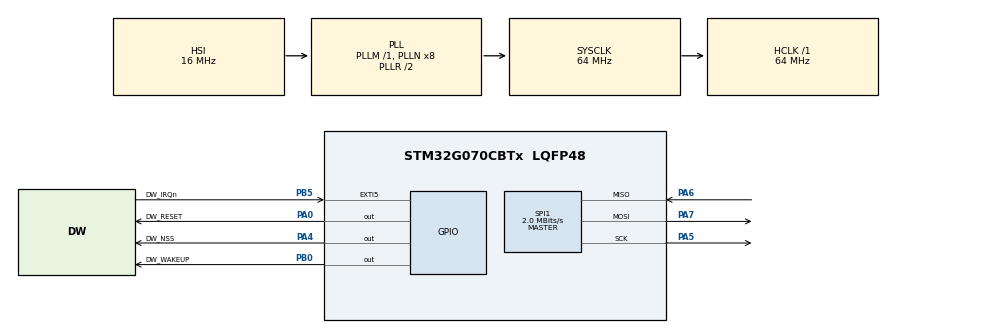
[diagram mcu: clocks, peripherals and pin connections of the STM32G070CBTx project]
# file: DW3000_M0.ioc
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Mcu.Family=STM32G0
Mcu.Name=STM32G070CBTx
Mcu.Package=LQFP48
NVIC.EXTI4_15_IRQn=true\:1\:0\:true\:false\:true\:true\:true\:true
PA0.GPIO_Label=DW_RESET
PA0.GPIO_Speed=GPIO_SPEED_FREQ_HIGH
PA0.Signal=GPIO_Output
PA13.Mode=Serial_Wire
PA13.Signal=SYS_SWDIO
PA14-BOOT0.Mode=Serial_Wire
PA14-BOOT0.Signal=SYS_SWCLK
PA4.GPIO_Label=DW_NSS
PA4.GPIO_Speed=GPIO_SPEED_FREQ_HIGH
PA4.PinState=GPIO_PIN_SET
PA4.Signal=GPIO_Output
PA5.Mode=Full_Duplex_Master
PA5.Signal=SPI1_SCK
PA6.Mode=Full_Duplex_Master
PA6.Signal=SPI1_MISO
PA7.Mode=Full_Duplex_Master
PA7.Signal=SPI1_MOSI
PB0.GPIO_Label=DW_WAKEUP
PB0.GPIO_Speed=GPIO_SPEED_FREQ_HIGH
PB0.Signal=GPIO_Output
PB5.GPIO_Label=DW_IRQn
PB5.GPIO_PuPd=GPIO_PULLDOWN
PB5.Signal=GPXTI5
PF0-OSC_IN\ (PF0).Mode=HSE-External-Clock-Source
PF0-OSC_IN\ (PF0).Signal=RCC_OSC_IN
ProjectManager.HeapSize=0x200
ProjectManager.StackSize=0x400
ProjectManager.TargetToolchain=MDK-ARM V5.27
RCC.ADCFreq_Value=64000000
RCC.AHBFreq_Value=64000000
RCC.CortexFreq_Value=64000000
RCC.EXTERNAL_CLOCK_VALUE=48000
RCC.HCLKFreq_Value=64000000
RCC.HSE_VALUE=8000000
RCC.HSI_VALUE=16000000
RCC.LSE_VALUE=32768
RCC.SYSCLKFreq_VALUE=64000000
RCC.SYSCLKSource=RCC_SYSCLKSOURCE_PLLCLK
RCC.VCOOutputFreq_Value=128000000
SPI1.BaudRatePrescaler=SPI_BAUDRATEPRESCALER_32
SPI1.CalculateBaudRate=2.0 MBits/s
SPI1.DataSize=SPI_DATASIZE_8BIT
SPI1.Direction=SPI_DIRECTION_2LINES
SPI1.Mode=SPI_MODE_MASTER
SPI1.VirtualType=VM_MASTER
board=custom

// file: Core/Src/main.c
/* USER CODE BEGIN Header */
/**
  ******************************************************************************
  * @file           : main.c
  * @brief          : Main program body
  ******************************************************************************
  * @attention
  *
  * Copyright (c) 2025 STMicroelectronics.
  * All rights reserved.
  *
  * This software is licensed under terms that can be found in the LICENSE file
  * in the root directory of this software component.
  * If no LICENSE file comes with this software, it is provided AS-IS.
  *
  ******************************************************************************
  */
/* USER CODE END Header */
#include "main.h"

/* USER CODE BEGIN Includes */
#include "port.h"
#include "examples_defines.h"
/* USER CODE END Includes */

SPI_HandleTypeDef hspi1;

void SystemClock_Config(void);
static void MX_GPIO_Init(void);
static void MX_SPI1_Init(void);

/* USER CODE BEGIN 0 */
#define UNIT_TEST 0
extern example_ptr example_pointer;
extern int unit_test_main(void);
/* USER CODE END 0 */

int main(void)
{

  /* MCU Configuration--------------------------------------------------------*/

  /* Reset of all peripherals, Initializes the Flash interface and the Systick. */
  HAL_Init();

  /* Configure the system clock */
  SystemClock_Config();

  /* Initialize all configured peripherals */
  MX_GPIO_Init();
  MX_SPI1_Init();
  /* USER CODE BEGIN 2 */
	HAL_Delay(500);

	build_examples();
  /* disable IRQ from DW3000*/
  port_DisableEXT_IRQ();
  setup_DWICRSTnIRQ(0);
  if(UNIT_TEST)
  {
     unit_test_main();
  }
  else
  {

	  //Run the selected example as selected in example_selection.h
	  example_pointer();

  }
  /* USER CODE END 2 */

  /* Infinite loop */
  while (1)
  {

  }
}

void SystemClock_Config(void)
{
  RCC_OscInitTypeDef RCC_OscInitStruct = {0};
  RCC_ClkInitTypeDef RCC_ClkInitStruct = {0};

  /** Configure the main internal regulator output voltage
  */
  HAL_PWREx_ControlVoltageScaling(PWR_REGULATOR_VOLTAGE_SCALE1);

  /** Initializes the RCC Oscillators according to the specified parameters
  * in the RCC_OscInitTypeDef structure.
  */
  RCC_OscInitStruct.OscillatorType = RCC_OSCILLATORTYPE_HSI;
  RCC_OscInitStruct.HSIState = RCC_HSI_ON;
  RCC_OscInitStruct.HSIDiv = RCC_HSI_DIV1;
  RCC_OscInitStruct.HSICalibrationValue = RCC_HSICALIBRATION_DEFAULT;
  RCC_OscInitStruct.PLL.PLLState = RCC_PLL_ON;
  RCC_OscInitStruct.PLL.PLLSource = RCC_PLLSOURCE_HSI;
  RCC_OscInitStruct.PLL.PLLM = RCC_PLLM_DIV1;
  RCC_OscInitStruct.PLL.PLLN = 8;
  RCC_OscInitStruct.PLL.PLLP = RCC_PLLP_DIV2;
  RCC_OscInitStruct.PLL.PLLR = RCC_PLLR_DIV2;
  if (HAL_RCC_OscConfig(&RCC_OscInitStruct) != HAL_OK)
  {
    Error_Handler();
  }

  /** Initializes the CPU, AHB and APB buses clocks
  */
  RCC_ClkInitStruct.ClockType = RCC_CLOCKTYPE_HCLK|RCC_CLOCKTYPE_SYSCLK
                              |RCC_CLOCKTYPE_PCLK1;
  RCC_ClkInitStruct.SYSCLKSource = RCC_SYSCLKSOURCE_PLLCLK;
  RCC_ClkInitStruct.AHBCLKDivider = RCC_SYSCLK_DIV1;
  RCC_ClkInitStruct.APB1CLKDivider = RCC_HCLK_DIV1;

  if (HAL_RCC_ClockConfig(&RCC_ClkInitStruct, FLASH_LATENCY_2) != HAL_OK)
  {
    Error_Handler();
  }
}

static void MX_SPI1_Init(void)
{

  /* SPI1 parameter configuration*/
  hspi1.Instance = SPI1;
  hspi1.Init.Mode = SPI_MODE_MASTER;
  hspi1.Init.Direction = SPI_DIRECTION_2LINES;
  hspi1.Init.DataSize = SPI_DATASIZE_8BIT;
  hspi1.Init.CLKPolarity = SPI_POLARITY_LOW;
  hspi1.Init.CLKPhase = SPI_PHASE_1EDGE;
  hspi1.Init.NSS = SPI_NSS_SOFT;
  hspi1.Init.BaudRatePrescaler = SPI_BAUDRATEPRESCALER_32;
  hspi1.Init.FirstBit = SPI_FIRSTBIT_MSB;
  hspi1.Init.TIMode = SPI_TIMODE_DISABLE;
  hspi1.Init.CRCCalculation = SPI_CRCCALCULATION_DISABLE;
  hspi1.Init.CRCPolynomial = 7;
  hspi1.Init.CRCLength = SPI_CRC_LENGTH_DATASIZE;
  hspi1.Init.NSSPMode = SPI_NSS_PULSE_ENABLE;
  if (HAL_SPI_Init(&hspi1) != HAL_OK)
  {
    Error_Handler();
  }

}

static void MX_GPIO_Init(void)
{
  GPIO_InitTypeDef GPIO_InitStruct = {0};

  /* GPIO Ports Clock Enable */
  __HAL_RCC_GPIOF_CLK_ENABLE();
  __HAL_RCC_GPIOA_CLK_ENABLE();
  __HAL_RCC_GPIOB_CLK_ENABLE();

  /*Configure GPIO pin Output Level */
  HAL_GPIO_WritePin(DW_RESET_GPIO_Port, DW_RESET_Pin, GPIO_PIN_RESET);

  /*Configure GPIO pin Output Level */
  HAL_GPIO_WritePin(DW_NSS_GPIO_Port, DW_NSS_Pin, GPIO_PIN_SET);

  /*Configure GPIO pin Output Level */
  HAL_GPIO_WritePin(DW_WAKEUP_GPIO_Port, DW_WAKEUP_Pin, GPIO_PIN_RESET);

  /*Configure GPIO pins : DW_RESET_Pin DW_NSS_Pin */
  GPIO_InitStruct.Pin = DW_RESET_Pin|DW_NSS_Pin;
  GPIO_InitStruct.Mode = GPIO_MODE_OUTPUT_PP;
  GPIO_InitStruct.Pull = GPIO_NOPULL;
  GPIO_InitStruct.Speed = GPIO_SPEED_FREQ_HIGH;
  HAL_GPIO_Init(GPIOA, &GPIO_InitStruct);

  /*Configure GPIO pin : DW_WAKEUP_Pin */
  GPIO_InitStruct.Pin = DW_WAKEUP_Pin;
  GPIO_InitStruct.Mode = GPIO_MODE_OUTPUT_PP;
  GPIO_InitStruct.Pull = GPIO_NOPULL;
  GPIO_InitStruct.Speed = GPIO_SPEED_FREQ_HIGH;
  HAL_GPIO_Init(DW_WAKEUP_GPIO_Port, &GPIO_InitStruct);

  /*Configure GPIO pin : DW_IRQn_Pin */
  GPIO_InitStruct.Pin = DW_IRQn_Pin;
  GPIO_InitStruct.Mode = GPIO_MODE_IT_RISING;
  GPIO_InitStruct.Pull = GPIO_PULLDOWN;
  HAL_GPIO_Init(DW_IRQn_GPIO_Port, &GPIO_InitStruct);

  /* EXTI interrupt init*/
  HAL_NVIC_SetPriority(EXTI4_15_IRQn, 1, 0);
  HAL_NVIC_EnableIRQ(EXTI4_15_IRQn);

}

void Error_Handler(void)
{
  __disable_irq();
  while (1)
  {
  }
}
